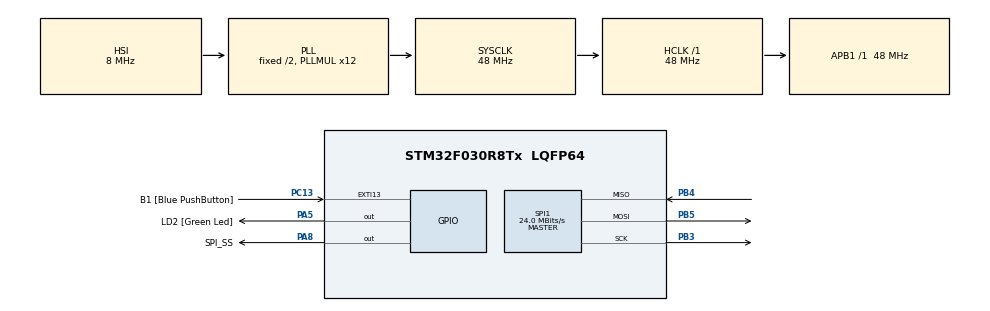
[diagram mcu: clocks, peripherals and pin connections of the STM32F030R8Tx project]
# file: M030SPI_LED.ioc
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Mcu.Family=STM32F0
Mcu.Name=STM32F030R8Tx
Mcu.Package=LQFP64
PA13.GPIO_Label=TMS
PA13.Signal=SYS_SWDIO
PA14.GPIO_Label=TCK
PA14.Signal=SYS_SWCLK
PA2.GPIO_Label=USART_TX
PA2.GPIO_Mode=GPIO_MODE_AF_PP
PA2.GPIO_PuPd=GPIO_NOPULL
PA2.GPIO_Speed=GPIO_SPEED_FREQ_LOW
PA2.Signal=USART2_TX
PA3.GPIO_Label=USART_RX
PA3.GPIO_Mode=GPIO_MODE_AF_PP
PA3.GPIO_PuPd=GPIO_NOPULL
PA3.GPIO_Speed=GPIO_SPEED_FREQ_LOW
PA3.Signal=USART2_RX
PA5.GPIO_Label=LD2 [Green Led]
PA5.GPIO_Mode=GPIO_MODE_OUTPUT_PP
PA5.GPIO_PuPd=GPIO_NOPULL
PA5.GPIO_Speed=GPIO_SPEED_FREQ_LOW
PA5.Signal=GPIO_Output
PA8.GPIO_Label=SPI_SS
PA8.Signal=GPIO_Output
PB3.Mode=Full_Duplex_Master
PB3.Signal=SPI1_SCK
PB4.Mode=Full_Duplex_Master
PB4.Signal=SPI1_MISO
PB5.Mode=Full_Duplex_Master
PB5.Signal=SPI1_MOSI
PC13.GPIO_Label=B1 [Blue PushButton]
PC13.GPIO_ModeDefaultEXTI=GPIO_MODE_IT_FALLING
PC13.Signal=GPXTI13
PC14-OSC32_IN.Signal=RCC_OSC32_IN
PC15-OSC32_OUT.Signal=RCC_OSC32_OUT
PF0-OSC_IN.Signal=RCC_OSC_IN
PF1-OSC_OUT.Signal=RCC_OSC_OUT
ProjectManager.HeapSize=0x200
ProjectManager.StackSize=0x400
ProjectManager.TargetToolchain=MDK-ARM V5
RCC.AHBFreq_Value=48000000
RCC.APB1Freq_Value=48000000
RCC.APB1TimFreq_Value=48000000
RCC.HCLKFreq_Value=48000000
RCC.PLLMUL=RCC_PLL_MUL12
RCC.SYSCLKFreq_VALUE=48000000
RCC.SYSCLKSource=RCC_SYSCLKSOURCE_PLLCLK
SPI1.BaudRatePrescaler=SPI_BAUDRATEPRESCALER_2
SPI1.CalculateBaudRate=24.0 MBits/s
SPI1.Direction=SPI_DIRECTION_2LINES
SPI1.Mode=SPI_MODE_MASTER
SPI1.VirtualType=VM_MASTER
board=NUCLEO-F030R8

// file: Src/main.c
/**
  ******************************************************************************
  * File Name          : main.c
  * Description        : Main program body
  ******************************************************************************
  ** This notice applies to any and all portions of this file
  * that are not between comment pairs USER CODE BEGIN and
  * USER CODE END. Other portions of this file, whether
  * inserted by the user or by software development tools
  * are owned by their respective copyright owners.
  *
  * COPYRIGHT(c) 2017 STMicroelectronics
  *
  * Redistribution and use in source and binary forms, with or without modification,
  * are permitted provided that the following conditions are met:
  *   1. Redistributions of source code must retain the above copyright notice,
  *      this list of conditions and the following disclaimer.
  *   2. Redistributions in binary form must reproduce the above copyright notice,
  *      this list of conditions and the following disclaimer in the documentation
  *      and/or other materials provided with the distribution.
  *   3. Neither the name of STMicroelectronics nor the names of its contributors
  *      may be used to endorse or promote products derived from this software
  *      without specific prior written permission.
  *
  * THIS SOFTWARE IS PROVIDED BY THE COPYRIGHT HOLDERS AND CONTRIBUTORS "AS IS"
  * AND ANY EXPRESS OR IMPLIED WARRANTIES, INCLUDING, BUT NOT LIMITED TO, THE
  * IMPLIED WARRANTIES OF MERCHANTABILITY AND FITNESS FOR A PARTICULAR PURPOSE ARE
  * DISCLAIMED. IN NO EVENT SHALL THE COPYRIGHT HOLDER OR CONTRIBUTORS BE LIABLE
  * FOR ANY DIRECT, INDIRECT, INCIDENTAL, SPECIAL, EXEMPLARY, OR CONSEQUENTIAL
  * DAMAGES (INCLUDING, BUT NOT LIMITED TO, PROCUREMENT OF SUBSTITUTE GOODS OR
  * SERVICES; LOSS OF USE, DATA, OR PROFITS; OR BUSINESS INTERRUPTION) HOWEVER
  * CAUSED AND ON ANY THEORY OF LIABILITY, WHETHER IN CONTRACT, STRICT LIABILITY,
  * OR TORT (INCLUDING NEGLIGENCE OR OTHERWISE) ARISING IN ANY WAY OUT OF THE USE
  * OF THIS SOFTWARE, EVEN IF ADVISED OF THE POSSIBILITY OF SUCH DAMAGE.
  *
  ******************************************************************************
  */
#include "main.h"
#include "stm32f0xx_hal.h"
#include "drv_Max7219.h"

SPI_HandleTypeDef hspi1;

/* USER CODE BEGIN PV */
/* Private variables ---------------------------------------------------------*/

/* USER CODE END PV */

void SystemClock_Config(void);
static void MX_GPIO_Init(void);
static void MX_SPI1_Init(void);

/* USER CODE BEGIN PFP */
/* Private function prototypes -----------------------------------------------*/

/* USER CODE END PFP */

int main(void)
{

  /* MCU Configuration----------------------------------------------------------*/

  /* Reset of all peripherals, Initializes the Flash interface and the Systick. */
  HAL_Init();

  /* Configure the system clock */
  SystemClock_Config();

  /* Initialize all configured peripherals */
  MX_GPIO_Init();
  MX_SPI1_Init();

  /* USER CODE BEGIN 2 */
  //8x8LED  init
  LedControl(1);
  shutdown(0,false);
  setIntensity(0,8);
  clearDisplay(0);

  setLed(0, 4, 3, 1);
  HAL_Delay(100);
  setLed(0, 4, 3, 0);
  /* USER CODE END 2 */

  /* Infinite loop */
  while (1)
  {

  }

}

/** System Clock Configuration
*/
void SystemClock_Config(void)
{

  RCC_OscInitTypeDef RCC_OscInitStruct;
  RCC_ClkInitTypeDef RCC_ClkInitStruct;

    /**Initializes the CPU, AHB and APB busses clocks
    */
  RCC_OscInitStruct.OscillatorType = RCC_OSCILLATORTYPE_HSI;
  RCC_OscInitStruct.HSIState = RCC_HSI_ON;
  RCC_OscInitStruct.HSICalibrationValue = 16;
  RCC_OscInitStruct.PLL.PLLState = RCC_PLL_ON;
  RCC_OscInitStruct.PLL.PLLSource = RCC_PLLSOURCE_HSI;
  RCC_OscInitStruct.PLL.PLLMUL = RCC_PLL_MUL12;
  RCC_OscInitStruct.PLL.PREDIV = RCC_PREDIV_DIV1;
  if (HAL_RCC_OscConfig(&RCC_OscInitStruct) != HAL_OK)
  {
    _Error_Handler(__FILE__, __LINE__);
  }

    /**Initializes the CPU, AHB and APB busses clocks
    */
  RCC_ClkInitStruct.ClockType = RCC_CLOCKTYPE_HCLK|RCC_CLOCKTYPE_SYSCLK
                              |RCC_CLOCKTYPE_PCLK1;
  RCC_ClkInitStruct.SYSCLKSource = RCC_SYSCLKSOURCE_PLLCLK;
  RCC_ClkInitStruct.AHBCLKDivider = RCC_SYSCLK_DIV1;
  RCC_ClkInitStruct.APB1CLKDivider = RCC_HCLK_DIV1;

  if (HAL_RCC_ClockConfig(&RCC_ClkInitStruct, FLASH_LATENCY_1) != HAL_OK)
  {
    _Error_Handler(__FILE__, __LINE__);
  }

    /**Configure the Systick interrupt time
    */
  HAL_SYSTICK_Config(HAL_RCC_GetHCLKFreq()/1000);

    /**Configure the Systick
    */
  HAL_SYSTICK_CLKSourceConfig(SYSTICK_CLKSOURCE_HCLK);

  /* SysTick_IRQn interrupt configuration */
  HAL_NVIC_SetPriority(SysTick_IRQn, 0, 0);
}

/* SPI1 init function */
static void MX_SPI1_Init(void)
{

  hspi1.Instance = SPI1;
  hspi1.Init.Mode = SPI_MODE_MASTER;
  hspi1.Init.Direction = SPI_DIRECTION_2LINES;
  hspi1.Init.DataSize = SPI_DATASIZE_4BIT;
  hspi1.Init.CLKPolarity = SPI_POLARITY_LOW;
  hspi1.Init.CLKPhase = SPI_PHASE_1EDGE;
  hspi1.Init.NSS = SPI_NSS_SOFT;
  hspi1.Init.BaudRatePrescaler = SPI_BAUDRATEPRESCALER_2;
  hspi1.Init.FirstBit = SPI_FIRSTBIT_MSB;
  hspi1.Init.TIMode = SPI_TIMODE_DISABLE;
  hspi1.Init.CRCCalculation = SPI_CRCCALCULATION_DISABLE;
  hspi1.Init.CRCPolynomial = 7;
  hspi1.Init.CRCLength = SPI_CRC_LENGTH_DATASIZE;
  hspi1.Init.NSSPMode = SPI_NSS_PULSE_ENABLE;
  if (HAL_SPI_Init(&hspi1) != HAL_OK)
  {
    _Error_Handler(__FILE__, __LINE__);
  }

}

/** Configure pins as
        * Analog
        * Input
        * Output
        * EVENT_OUT
        * EXTI
     PA2   ------> USART2_TX
     PA3   ------> USART2_RX
*/
static void MX_GPIO_Init(void)
{

  GPIO_InitTypeDef GPIO_InitStruct;

  /* GPIO Ports Clock Enable */
  __HAL_RCC_GPIOC_CLK_ENABLE();
  __HAL_RCC_GPIOF_CLK_ENABLE();
  __HAL_RCC_GPIOA_CLK_ENABLE();
  __HAL_RCC_GPIOB_CLK_ENABLE();

  /*Configure GPIO pin Output Level */
  HAL_GPIO_WritePin(GPIOA, LD2_Pin|SPI_SS_Pin, GPIO_PIN_RESET);

  /*Configure GPIO pin : B1_Pin */
  GPIO_InitStruct.Pin = B1_Pin;
  GPIO_InitStruct.Mode = GPIO_MODE_IT_FALLING;
  GPIO_InitStruct.Pull = GPIO_NOPULL;
  HAL_GPIO_Init(B1_GPIO_Port, &GPIO_InitStruct);

  /*Configure GPIO pins : USART_TX_Pin USART_RX_Pin */
  GPIO_InitStruct.Pin = USART_TX_Pin|USART_RX_Pin;
  GPIO_InitStruct.Mode = GPIO_MODE_AF_PP;
  GPIO_InitStruct.Pull = GPIO_NOPULL;
  GPIO_InitStruct.Speed = GPIO_SPEED_FREQ_LOW;
  GPIO_InitStruct.Alternate = GPIO_AF1_USART2;
  HAL_GPIO_Init(GPIOA, &GPIO_InitStruct);

  /*Configure GPIO pins : LD2_Pin SPI_SS_Pin */
  GPIO_InitStruct.Pin = LD2_Pin|SPI_SS_Pin;
  GPIO_InitStruct.Mode = GPIO_MODE_OUTPUT_PP;
  GPIO_InitStruct.Pull = GPIO_NOPULL;
  GPIO_InitStruct.Speed = GPIO_SPEED_FREQ_LOW;
  HAL_GPIO_Init(GPIOA, &GPIO_InitStruct);

}

void _Error_Handler(char * file, int line)
{
  while(1)
  {
  }
}

/************************ (C) COPYRIGHT STMicroelectronics *****END OF FILE****/
